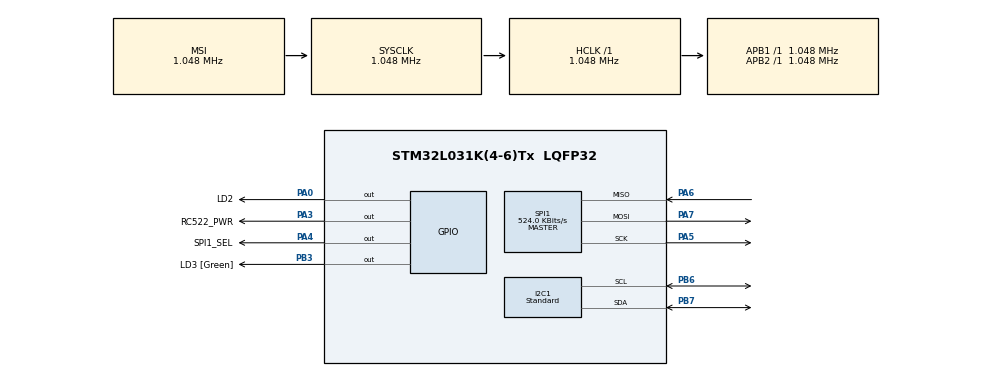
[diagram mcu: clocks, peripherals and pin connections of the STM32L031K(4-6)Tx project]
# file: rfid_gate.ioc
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Mcu.Family=STM32L0
RCC.MSI_VALUE=1048000
PC15-OSC32_OUT.Mode=LSE-External-Oscillator
PA0-CK_IN.GPIO_Label=LD2
PA6.Mode=Full_Duplex_Master
PA7.Mode=Full_Duplex_Master
I2C1.I2C_Speed_Mode=I2C_Standard
SPI1.VirtualType=VM_MASTER
PA14.GPIO_Label=TCK
NVIC.PVD_IRQn=true\:0\:0\:false\:false\:true\:true\:true
PC14-OSC32_IN.Signal=RCC_OSC32_IN
ProjectManager.StackSize=0x400
PA13.Signal=SYS_SWDIO
RCC.HSI16_VALUE=16000000
RCC.PLLDIV=RCC_PLLDIV_3
PA4.PinState=GPIO_PIN_RESET
ProjectManager.TargetToolchain=STM32CubeIDE
SPI1.Direction=SPI_DIRECTION_2LINES
RCC.HCLKFreq_Value=1048000
RCC.APB2TimFreq_Value=1048000
PB6.Signal=I2C1_SCL
I2C1.Timing=0x00000202
PB6.Mode=I2C
SPI1.CalculateBaudRate=524.0 KBits/s
PC15-OSC32_OUT.Signal=RCC_OSC32_OUT
RCC.AHBFreq_Value=1048000
PA5.Signal=SPI1_SCK
RCC.HSE_VALUE=8000000
PA4.GPIO_PuPd=GPIO_NOPULL
board=NUCLEO-L031K6
RCC.VCOOutputFreq_Value=48000000
PA0-CK_IN.Signal=GPIO_Output
RCC.APB2Freq_Value=1048000
PC14-OSC32_IN.Mode=LSE-External-Oscillator
SPI1.Mode=SPI_MODE_MASTER
PA14.Mode=Serial_Wire
PB7.Signal=I2C1_SDA
PA13.Mode=Serial_Wire
Mcu.Name=STM32L031K(4-6)Tx
PA13.GPIO_Label=TMS
PB3.Signal=GPIO_Output
PA4.Signal=GPIO_Output
RCC.SYSCLKFreq_VALUE=1048000
Mcu.Package=LQFP32
PA6.Signal=SPI1_MISO
PB7.Mode=I2C
PA14.Signal=SYS_SWCLK
ProjectManager.HeapSize=0x200
PA4.GPIO_ModeDefaultOutputPP=GPIO_MODE_OUTPUT_PP
RCC.HSI_VALUE=16000000
RCC.APB1TimFreq_Value=1048000
RCC.APB1Freq_Value=1048000
PA4.GPIO_Label=SPI1_SEL
RCC.MSIClockRange=RCC_MSIRANGE_4
RCC.HSI48_VALUE=48000000
PA3.GPIO_Label=RC522_PWR
PA3.Signal=GPIO_Output
PA5.Mode=Full_Duplex_Master
PA7.Signal=SPI1_MOSI
PB3.GPIO_Label=LD3 [Green]

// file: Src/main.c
/* USER CODE BEGIN Header */
/**
 ******************************************************************************
 * @file           : main.c
 * @brief          : Main program body
 ******************************************************************************
 * @attention
 *
 * <h2><center>&copy; Copyright (c) 2020 STMicroelectronics.
 * All rights reserved.</center></h2>
 *
 * This software component is licensed by ST under BSD 3-Clause license,
 * the "License"; You may not use this file except in compliance with the
 * License. You may obtain a copy of the License at:
 *                        opensource.org/licenses/BSD-3-Clause
 *
 ******************************************************************************
 */
/* USER CODE END Header */

#include "main.h"
#include "i2c.h"
#include "spi.h"
#include "gpio.h"

/* USER CODE BEGIN Includes */
#include "rc522.h"
#include "tagMemory.h"
#include "tasker.h"
#include "tagMemory.h"
#include "tagAction.h"
#include "eeprom.h"
/* USER CODE END Includes */

void SystemClock_Config(void);

int main(void)
{

  /* MCU Configuration--------------------------------------------------------*/

  /* Reset of all peripherals, Initializes the Flash interface and the Systick. */
  HAL_Init();

  /* Configure the system clock */
  SystemClock_Config();

  /* Initialize all configured peripherals */
  MX_GPIO_Init();
  MX_SPI1_Init();
  MX_I2C1_Init();

  /* Infinite loop */
  /* USER CODE BEGIN WHILE */
	MFRC522_PowerUp();
	MFRC522_Init();

	tag_init();
	tag_erase_all();

	tag_wait_if_no_key();

	Task sense_task = task_make(200, tag_auth);
	task_start(sense_task);

	while (1)
	{
		task_state(sense_task, NULL);

    /* USER CODE END WHILE */

	}
}

void SystemClock_Config(void)
{
  RCC_OscInitTypeDef RCC_OscInitStruct = {0};
  RCC_ClkInitTypeDef RCC_ClkInitStruct = {0};
  RCC_PeriphCLKInitTypeDef PeriphClkInit = {0};

  /** Configure the main internal regulator output voltage
  */
  __HAL_PWR_VOLTAGESCALING_CONFIG(PWR_REGULATOR_VOLTAGE_SCALE1);
  /** Initializes the CPU, AHB and APB busses clocks
  */
  RCC_OscInitStruct.OscillatorType = RCC_OSCILLATORTYPE_MSI;
  RCC_OscInitStruct.MSIState = RCC_MSI_ON;
  RCC_OscInitStruct.MSICalibrationValue = 0;
  RCC_OscInitStruct.MSIClockRange = RCC_MSIRANGE_4;
  RCC_OscInitStruct.PLL.PLLState = RCC_PLL_NONE;
  if (HAL_RCC_OscConfig(&RCC_OscInitStruct) != HAL_OK)
  {
    Error_Handler();
  }
  /** Initializes the CPU, AHB and APB busses clocks
  */
  RCC_ClkInitStruct.ClockType = RCC_CLOCKTYPE_HCLK|RCC_CLOCKTYPE_SYSCLK
                              |RCC_CLOCKTYPE_PCLK1|RCC_CLOCKTYPE_PCLK2;
  RCC_ClkInitStruct.SYSCLKSource = RCC_SYSCLKSOURCE_MSI;
  RCC_ClkInitStruct.AHBCLKDivider = RCC_SYSCLK_DIV1;
  RCC_ClkInitStruct.APB1CLKDivider = RCC_HCLK_DIV1;
  RCC_ClkInitStruct.APB2CLKDivider = RCC_HCLK_DIV1;

  if (HAL_RCC_ClockConfig(&RCC_ClkInitStruct, FLASH_LATENCY_0) != HAL_OK)
  {
    Error_Handler();
  }
  PeriphClkInit.PeriphClockSelection = RCC_PERIPHCLK_I2C1;
  PeriphClkInit.I2c1ClockSelection = RCC_I2C1CLKSOURCE_PCLK1;
  if (HAL_RCCEx_PeriphCLKConfig(&PeriphClkInit) != HAL_OK)
  {
    Error_Handler();
  }
}

void Error_Handler(void)
{
}

/************************ (C) COPYRIGHT STMicroelectronics *****END OF FILE****/
